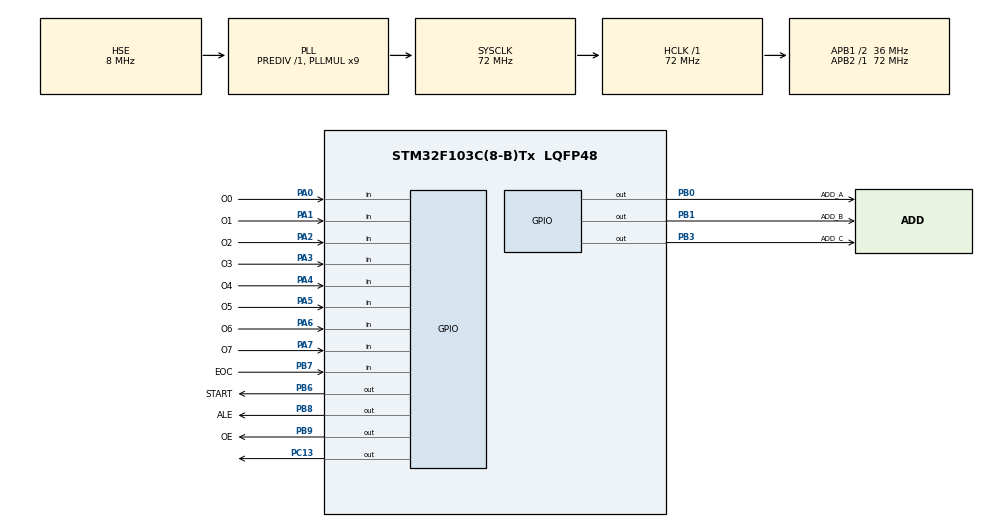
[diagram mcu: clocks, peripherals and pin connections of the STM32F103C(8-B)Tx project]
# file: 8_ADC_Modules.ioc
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Mcu.Family=STM32F1
RCC.PLLSourceVirtual=RCC_PLLSOURCE_HSE
PD1-OSC_OUT.Mode=HSE-External-Oscillator
PB9.GPIO_Label=OE
PC13-TAMPER-RTC.Signal=GPIO_Output
PA6.GPIO_Label=O6
PB0.GPIO_Label=ADD_A
PB6.GPIO_Label=START
PD0-OSC_IN.Signal=RCC_OSC_IN
RCC.APB1CLKDivider=RCC_HCLK_DIV2
RCC.SYSCLKSource=RCC_SYSCLKSOURCE_PLLCLK
ProjectManager.StackSize=0x400
PA0-WKUP.GPIO_Label=O0
PA0-WKUP.Signal=GPIO_Input
PD1-OSC_OUT.Signal=RCC_OSC_OUT
PA13.Signal=SYS_JTMS-SWDIO
PB8.GPIO_Label=ALE
ProjectManager.TargetToolchain=STM32CubeIDE
RCC.HCLKFreq_Value=72000000
RCC.APB2TimFreq_Value=72000000
PB6.Signal=GPIO_Output
RCC.USBFreq_Value=72000000
PA1.Signal=GPIO_Input
RCC.AHBFreq_Value=72000000
PD0-OSC_IN.Mode=HSE-External-Oscillator
PA5.Signal=GPIO_Input
board=custom
RCC.PLLMUL=RCC_PLL_MUL9
RCC.APB2Freq_Value=72000000
PA14.Mode=Serial_Wire
PB1.GPIO_Label=ADD_B
PA1.GPIO_Label=O1
PB7.Signal=GPIO_Input
PA13.Mode=Serial_Wire
Mcu.Name=STM32F103C(8-B)Tx
PA2.Signal=GPIO_Input
PB7.GPIO_Label=EOC
PB3.Signal=GPIO_Output
PA4.Signal=GPIO_Input
RCC.SYSCLKFreq_VALUE=72000000
Mcu.Package=LQFP48
PB9.Signal=GPIO_Output
PA6.Signal=GPIO_Input
PB1.Signal=GPIO_Output
PA7.GPIO_Label=O7
PA5.GPIO_Label=O5
PA2.GPIO_Label=O2
PA14.Signal=SYS_JTCK-SWCLK
ProjectManager.HeapSize=0x200
NVIC.PriorityGroup=NVIC_PRIORITYGROUP_4
RCC.APB1TimFreq_Value=72000000
PB8.Signal=GPIO_Output
RCC.APB1Freq_Value=36000000
PB0.Signal=GPIO_Output
PA4.GPIO_Label=O4
PA3.GPIO_Label=O3
PA3.Signal=GPIO_Input
PA7.Signal=GPIO_Input
PB3.GPIO_Label=ADD_C

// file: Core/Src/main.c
/* USER CODE BEGIN Header */
/**
  ******************************************************************************
  * @file           : main.c
  * @brief          : Main program body
  ******************************************************************************
  * @attention
  *
  * <h2><center>&copy; Copyright (c) 2021 STMicroelectronics.
  * All rights reserved.</center></h2>
  *
  * This software component is licensed by ST under BSD 3-Clause license,
  * the "License"; You may not use this file except in compliance with the
  * License. You may obtain a copy of the License at:
  *                        opensource.org/licenses/BSD-3-Clause
  *
  ******************************************************************************
  */
/* USER CODE END Header */
#include "main.h"

/* USER CODE BEGIN Includes */
#include "adc0809.h"
/* USER CODE END Includes */

void SystemClock_Config(void);
static void MX_GPIO_Init(void);

int main(void)
{

  /* MCU Configuration--------------------------------------------------------*/

  /* Reset of all peripherals, Initializes the Flash interface and the Systick. */
  HAL_Init();

  /* Configure the system clock */
  SystemClock_Config();

  /* Initialize all configured peripherals */
  MX_GPIO_Init();
  /* USER CODE BEGIN 2 */
//  ADC0809_clk_init();
 // DelayInit();
  /* USER CODE END 2 */

  /* Infinite loop */
  while (1)
  {

    /* USER CODE BEGIN 3 */
	  uint8_t adc_value = ADC0809_Read(3);//volume register on the module
	  float voltage = (3.3*adc_value)/256;
	  HAL_GPIO_TogglePin(GPIOC, GPIO_PIN_13);
	  HAL_Delay(1000);
	//  DelayMs(1000);
  }
  /* USER CODE END 3 */
}

void SystemClock_Config(void)
{
  RCC_OscInitTypeDef RCC_OscInitStruct = {0};
  RCC_ClkInitTypeDef RCC_ClkInitStruct = {0};

  /** Initializes the RCC Oscillators according to the specified parameters
  * in the RCC_OscInitTypeDef structure.
  */
  RCC_OscInitStruct.OscillatorType = RCC_OSCILLATORTYPE_HSE;
  RCC_OscInitStruct.HSEState = RCC_HSE_ON;
  RCC_OscInitStruct.HSEPredivValue = RCC_HSE_PREDIV_DIV1;
  RCC_OscInitStruct.HSIState = RCC_HSI_ON;
  RCC_OscInitStruct.PLL.PLLState = RCC_PLL_ON;
  RCC_OscInitStruct.PLL.PLLSource = RCC_PLLSOURCE_HSE;
  RCC_OscInitStruct.PLL.PLLMUL = RCC_PLL_MUL9;
  if (HAL_RCC_OscConfig(&RCC_OscInitStruct) != HAL_OK)
  {
    Error_Handler();
  }
  /** Initializes the CPU, AHB and APB buses clocks
  */
  RCC_ClkInitStruct.ClockType = RCC_CLOCKTYPE_HCLK|RCC_CLOCKTYPE_SYSCLK
                              |RCC_CLOCKTYPE_PCLK1|RCC_CLOCKTYPE_PCLK2;
  RCC_ClkInitStruct.SYSCLKSource = RCC_SYSCLKSOURCE_PLLCLK;
  RCC_ClkInitStruct.AHBCLKDivider = RCC_SYSCLK_DIV1;
  RCC_ClkInitStruct.APB1CLKDivider = RCC_HCLK_DIV2;
  RCC_ClkInitStruct.APB2CLKDivider = RCC_HCLK_DIV1;

  if (HAL_RCC_ClockConfig(&RCC_ClkInitStruct, FLASH_LATENCY_2) != HAL_OK)
  {
    Error_Handler();
  }
}

static void MX_GPIO_Init(void)
{
  GPIO_InitTypeDef GPIO_InitStruct = {0};

  /* GPIO Ports Clock Enable */
  __HAL_RCC_GPIOC_CLK_ENABLE();
  __HAL_RCC_GPIOD_CLK_ENABLE();
  __HAL_RCC_GPIOA_CLK_ENABLE();
  __HAL_RCC_GPIOB_CLK_ENABLE();

  /*Configure GPIO pin Output Level */
  HAL_GPIO_WritePin(GPIOC, GPIO_PIN_13, GPIO_PIN_RESET);

  /*Configure GPIO pin Output Level */
  HAL_GPIO_WritePin(GPIOB, ADD_A_Pin|ADD_B_Pin|ADD_C_Pin|START_Pin
                          |ALE_Pin|OE_Pin, GPIO_PIN_RESET);

  /*Configure GPIO pin : PC13 */
  GPIO_InitStruct.Pin = GPIO_PIN_13;
  GPIO_InitStruct.Mode = GPIO_MODE_OUTPUT_PP;
  GPIO_InitStruct.Pull = GPIO_NOPULL;
  GPIO_InitStruct.Speed = GPIO_SPEED_FREQ_LOW;
  HAL_GPIO_Init(GPIOC, &GPIO_InitStruct);

  /*Configure GPIO pins : O0_Pin O1_Pin O2_Pin O3_Pin
                           O4_Pin O5_Pin O6_Pin O7_Pin */
  GPIO_InitStruct.Pin = O0_Pin|O1_Pin|O2_Pin|O3_Pin
                          |O4_Pin|O5_Pin|O6_Pin|O7_Pin;
  GPIO_InitStruct.Mode = GPIO_MODE_INPUT;
  GPIO_InitStruct.Pull = GPIO_NOPULL;
  HAL_GPIO_Init(GPIOA, &GPIO_InitStruct);

  /*Configure GPIO pins : ADD_A_Pin ADD_B_Pin ADD_C_Pin START_Pin
                           ALE_Pin OE_Pin */
  GPIO_InitStruct.Pin = ADD_A_Pin|ADD_B_Pin|ADD_C_Pin|START_Pin
                          |ALE_Pin|OE_Pin;
  GPIO_InitStruct.Mode = GPIO_MODE_OUTPUT_PP;
  GPIO_InitStruct.Pull = GPIO_NOPULL;
  GPIO_InitStruct.Speed = GPIO_SPEED_FREQ_LOW;
  HAL_GPIO_Init(GPIOB, &GPIO_InitStruct);

  /*Configure GPIO pin : EOC_Pin */
  GPIO_InitStruct.Pin = EOC_Pin;
  GPIO_InitStruct.Mode = GPIO_MODE_INPUT;
  GPIO_InitStruct.Pull = GPIO_NOPULL;
  HAL_GPIO_Init(EOC_GPIO_Port, &GPIO_InitStruct);

}

void Error_Handler(void)
{
  __disable_irq();
  while (1)
  {
  }
}

/************************ (C) COPYRIGHT STMicroelectronics *****END OF FILE****/
